AUTOSAR XML (schema 4-0-3)
standard types defined: Boolean, UInt16, UInt32
package /AUTOSAR_Platform/DataConstrs
  range DC_Boolean: raw 0..1
  range DC_UInt16: raw 0..65535
package /PATAC/MSM/ComponentTypes
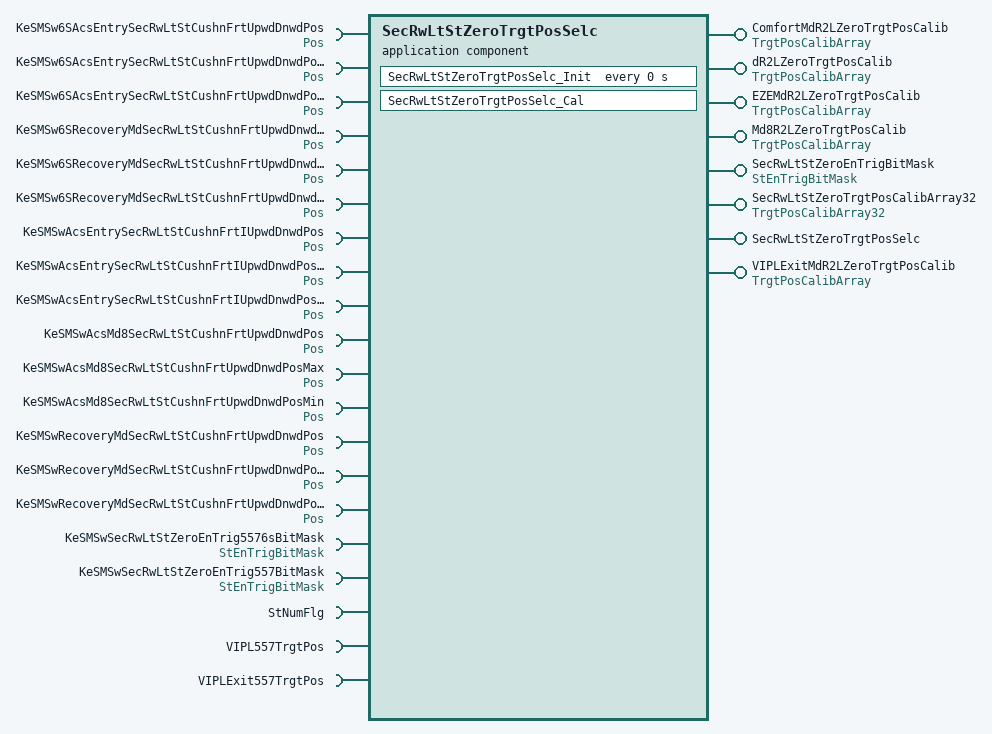
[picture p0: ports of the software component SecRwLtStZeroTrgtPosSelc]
  application sw component type SecRwLtStZeroTrgtPosSelc
    8 x provide port:
      ComfortMdR2LZeroTrgtPosCalib: nonqueued-sender-com-spec{data-element=TrgtPosArray, init-value=[4095, 4095, 4095]}, provided-interface=TrgtPosCalibArray
      dR2LZeroTrgtPosCalib: nonqueued-sender-com-spec{data-element=TrgtPosArray, init-value=[4095, 4095, 4095]}, provided-interface=TrgtPosCalibArray
      EZEMdR2LZeroTrgtPosCalib: nonqueued-sender-com-spec{data-element=TrgtPosArray, init-value=[4095, 4095, 4095]}, provided-interface=TrgtPosCalibArray
      Md8R2LZeroTrgtPosCalib: nonqueued-sender-com-spec{data-element=TrgtPosArray, init-value=[4095, 4095, 4095]}, provided-interface=TrgtPosCalibArray
      SecRwLtStZeroEnTrigBitMask: nonqueued-sender-com-spec{data-element=Val, init-value=0}, provided-interface=StEnTrigBitMask
      SecRwLtStZeroTrgtPosCalibArray32: nonqueued-sender-com-spec{data-element=TrgtPosArray32, init-value=96 x 4095}, provided-interface=TrgtPosCalibArray32
      SecRwLtStZeroTrgtPosSelc: server-com-spec{operation=Cal, queue-length=1}, provided-interface=SecRwLtStZeroTrgtPosSelc
      VIPLExitMdR2LZeroTrgtPosCalib: nonqueued-sender-com-spec{data-element=TrgtPosArray, init-value=[4095, 4095, 4095]}, provided-interface=TrgtPosCalibArray
    20 x require port:
      KeSMSw6SAcsEntrySecRwLtStCushnFrtUpwdDnwdPos: parameter-require-com-spec{init-value=0, parameter=Pos/Val}, required-interface=Pos
      KeSMSw6SAcsEntrySecRwLtStCushnFrtUpwdDnwdPosMax: parameter-require-com-spec{init-value=0, parameter=Pos/Val}, required-interface=Pos
      KeSMSw6SAcsEntrySecRwLtStCushnFrtUpwdDnwdPosMin: parameter-require-com-spec{init-value=0, parameter=Pos/Val}, required-interface=Pos
      KeSMSw6SRecoveryMdSecRwLtStCushnFrtUpwdDnwdPos: parameter-require-com-spec{init-value=0, parameter=Pos/Val}, required-interface=Pos
      KeSMSw6SRecoveryMdSecRwLtStCushnFrtUpwdDnwdPosMax: parameter-require-com-spec{init-value=0, parameter=Pos/Val}, required-interface=Pos
      KeSMSw6SRecoveryMdSecRwLtStCushnFrtUpwdDnwdPosMin: parameter-require-com-spec{init-value=0, parameter=Pos/Val}, required-interface=Pos
      KeSMSwAcsEntrySecRwLtStCushnFrtIUpwdDnwdPos: parameter-require-com-spec{init-value=0, parameter=Pos/Val}, required-interface=Pos
      KeSMSwAcsEntrySecRwLtStCushnFrtIUpwdDnwdPosMax: parameter-require-com-spec{init-value=0, parameter=Pos/Val}, required-interface=Pos
      KeSMSwAcsEntrySecRwLtStCushnFrtIUpwdDnwdPosMin: parameter-require-com-spec{init-value=0, parameter=Pos/Val}, required-interface=Pos
      KeSMSwAcsMd8SecRwLtStCushnFrtUpwdDnwdPos: parameter-require-com-spec{init-value=0, parameter=Pos/Val}, required-interface=Pos
      KeSMSwAcsMd8SecRwLtStCushnFrtUpwdDnwdPosMax: parameter-require-com-spec{init-value=0, parameter=Pos/Val}, required-interface=Pos
      KeSMSwAcsMd8SecRwLtStCushnFrtUpwdDnwdPosMin: parameter-require-com-spec{init-value=0, parameter=Pos/Val}, required-interface=Pos
      KeSMSwRecoveryMdSecRwLtStCushnFrtUpwdDnwdPos: parameter-require-com-spec{init-value=0, parameter=Pos/Val}, required-interface=Pos
      KeSMSwRecoveryMdSecRwLtStCushnFrtUpwdDnwdPosMax: parameter-require-com-spec{init-value=0, parameter=Pos/Val}, required-interface=Pos
      KeSMSwRecoveryMdSecRwLtStCushnFrtUpwdDnwdPosMin: parameter-require-com-spec{init-value=0, parameter=Pos/Val}, required-interface=Pos
      KeSMSwSecRwLtStZeroEnTrig5576sBitMask: parameter-require-com-spec{init-value=6153, parameter=StEnTrigBitMask/Val}, required-interface=StEnTrigBitMask
      KeSMSwSecRwLtStZeroEnTrig557BitMask: parameter-require-com-spec{init-value=6153, parameter=StEnTrigBitMask/Val}, required-interface=StEnTrigBitMask
      StNumFlg: required-interface=StNumFlg
        required-com-specs:
          data-element=Is4s, filter=data-filter-type=ALWAYS, init-value=0
          data-element=Is6s, filter=data-filter-type=ALWAYS, init-value=0
          data-element=Is6s7s, filter=data-filter-type=ALWAYS, init-value=0
          data-element=Is7s, filter=data-filter-type=ALWAYS, init-value=0
      VIPL557TrgtPos: required-com-specs=[VIPL557TrgtPos/Get, VIPL557TrgtPos/Set], required-interface=VIPL557TrgtPos
      VIPLExit557TrgtPos: required-com-specs=[VIPLExit557TrgtPos/Get, VIPLExit557TrgtPos/Set], required-interface=VIPLExit557TrgtPos
    behavior SecRwLtStZeroTrgtPosSelc_InternalBehavior
      operation invoked event OIT_SecRwLtStZeroTrgtPosSelc_Cal_SecRwLtStZeroTrgtPosSelc_Cal: start-on-event=SecRwLtStZeroTrgtPosSelc_Cal, operation=SecRwLtStZeroTrgtPosSelc.Cal
      timing event SecRwLtStZeroTrgtPosSelc_InitEvent: start-on-event=SecRwLtStZeroTrgtPosSelc_Init, period=0
      runnable SecRwLtStZeroTrgtPosSelc_Cal
        data-receive-point-by-arguments:
          4 x access:
            REC_StNumFlg_Is4s: accessed-variable=StNumFlg.Is4s
            REC_StNumFlg_Is6s: accessed-variable=StNumFlg.Is6s
            REC_StNumFlg_Is6s7s: accessed-variable=StNumFlg.Is6s7s
            REC_StNumFlg_Is7s: accessed-variable=StNumFlg.Is7s
        data-send-points:
          7 x access:
            SEND_ComfortMdR2LZeroTrgtPosCalib_TrgtPosArray: accessed-variable=ComfortMdR2LZeroTrgtPosCalib.TrgtPosArray
            SEND_EZEMdR2LZeroTrgtPosCalib_TrgtPosArray: accessed-variable=EZEMdR2LZeroTrgtPosCalib.TrgtPosArray
            SEND_Md8R2LZeroTrgtPosCalib_TrgtPosArray: accessed-variable=Md8R2LZeroTrgtPosCalib.TrgtPosArray
            SEND_SecRwLtStZeroEnTrigBitMask_Val: accessed-variable=SecRwLtStZeroEnTrigBitMask.Val
            SEND_SecRwLtStZeroTrgtPosCalibArray32_TrgtPosArray32: accessed-variable=SecRwLtStZeroTrgtPosCalibArray32.TrgtPosArray32
            SEND_VIPLExitMdR2LZeroTrgtPosCalib_TrgtPosArray: accessed-variable=VIPLExitMdR2LZeroTrgtPosCalib.TrgtPosArray
            SEND_VIPLMdR2LZeroTrgtPosCalib_TrgtPosArray: accessed-variable=dR2LZeroTrgtPosCalib.TrgtPosArray
        17 x parameter access:
          PA_KeSMSw6SAcsEntrySecRwLtStCushnFrtUpwdDnwdPos_Val: accessed-parameter=KeSMSw6SAcsEntrySecRwLtStCushnFrtUpwdDnwdPos.Val
          PA_KeSMSw6SAcsEntrySecRwLtStCushnFrtUpwdDnwdPosMax_Val: accessed-parameter=KeSMSw6SAcsEntrySecRwLtStCushnFrtUpwdDnwdPosMax.Val
          PA_KeSMSw6SAcsEntrySecRwLtStCushnFrtUpwdDnwdPosMin_Val: accessed-parameter=KeSMSw6SAcsEntrySecRwLtStCushnFrtUpwdDnwdPosMin.Val
          PA_KeSMSw6SRecoveryMdSecRwLtStCushnFrtUpwdDnwdPos_Val: accessed-parameter=KeSMSw6SRecoveryMdSecRwLtStCushnFrtUpwdDnwdPos.Val
          PA_KeSMSw6SRecoveryMdSecRwLtStCushnFrtUpwdDnwdPosMax_Val: accessed-parameter=KeSMSw6SRecoveryMdSecRwLtStCushnFrtUpwdDnwdPosMax.Val
          PA_KeSMSw6SRecoveryMdSecRwLtStCushnFrtUpwdDnwdPosMin_Val: accessed-parameter=KeSMSw6SRecoveryMdSecRwLtStCushnFrtUpwdDnwdPosMin.Val
          PA_KeSMSwAcsEntrySecRwLtStCushnFrtIUpwdDnwdPos_Val: accessed-parameter=KeSMSwAcsEntrySecRwLtStCushnFrtIUpwdDnwdPos.Val
          PA_KeSMSwAcsEntrySecRwLtStCushnFrtIUpwdDnwdPosMax_Val: accessed-parameter=KeSMSwAcsEntrySecRwLtStCushnFrtIUpwdDnwdPosMax.Val
          PA_KeSMSwAcsEntrySecRwLtStCushnFrtIUpwdDnwdPosMin_Val: accessed-parameter=KeSMSwAcsEntrySecRwLtStCushnFrtIUpwdDnwdPosMin.Val
          PA_KeSMSwAcsMd8SecRwLtStCushnFrtUpwdDnwdPos_Val: accessed-parameter=KeSMSwAcsMd8SecRwLtStCushnFrtUpwdDnwdPos.Val
          PA_KeSMSwAcsMd8SecRwLtStCushnFrtUpwdDnwdPosMax_Val: accessed-parameter=KeSMSwAcsMd8SecRwLtStCushnFrtUpwdDnwdPosMax.Val
          PA_KeSMSwAcsMd8SecRwLtStCushnFrtUpwdDnwdPosMin_Val: accessed-parameter=KeSMSwAcsMd8SecRwLtStCushnFrtUpwdDnwdPosMin.Val
          PA_KeSMSwRecoveryMdSecRwLtStCushnFrtUpwdDnwdPos_Val: accessed-parameter=KeSMSwRecoveryMdSecRwLtStCushnFrtUpwdDnwdPos.Val
          PA_KeSMSwRecoveryMdSecRwLtStCushnFrtUpwdDnwdPosMax_Val: accessed-parameter=KeSMSwRecoveryMdSecRwLtStCushnFrtUpwdDnwdPosMax.Val
          PA_KeSMSwRecoveryMdSecRwLtStCushnFrtUpwdDnwdPosMin_Val: accessed-parameter=KeSMSwRecoveryMdSecRwLtStCushnFrtUpwdDnwdPosMin.Val
          PA_KeSMSwSecRwLtStZeroEnTrig5576sBitMask_Val: accessed-parameter=KeSMSwSecRwLtStZeroEnTrig5576sBitMask.Val
          PA_KeSMSwSecRwLtStZeroEnTrig557BitMask_Val: accessed-parameter=KeSMSwSecRwLtStZeroEnTrig557BitMask.Val
        sync call SC_VIPL557TrgtPos_Get: operation=VIPL557TrgtPos.Get, timeout=0
        sync call SC_VIPLExit557TrgtPos_Get: operation=VIPLExit557TrgtPos.Get, timeout=0
      runnable SecRwLtStZeroTrgtPosSelc_Init
        17 x parameter access:
          PA_KeSMSw6SAcsEntrySecRwLtStCushnFrtUpwdDnwdPos_Val: accessed-parameter=KeSMSw6SAcsEntrySecRwLtStCushnFrtUpwdDnwdPos.Val
          PA_KeSMSw6SAcsEntrySecRwLtStCushnFrtUpwdDnwdPosMax_Val: accessed-parameter=KeSMSw6SAcsEntrySecRwLtStCushnFrtUpwdDnwdPosMax.Val
          PA_KeSMSw6SAcsEntrySecRwLtStCushnFrtUpwdDnwdPosMin_Val: accessed-parameter=KeSMSw6SAcsEntrySecRwLtStCushnFrtUpwdDnwdPosMin.Val
          PA_KeSMSw6SRecoveryMdSecRwLtStCushnFrtUpwdDnwdPos_Val: accessed-parameter=KeSMSw6SRecoveryMdSecRwLtStCushnFrtUpwdDnwdPos.Val
          PA_KeSMSw6SRecoveryMdSecRwLtStCushnFrtUpwdDnwdPosMax_Val: accessed-parameter=KeSMSw6SRecoveryMdSecRwLtStCushnFrtUpwdDnwdPosMax.Val
          PA_KeSMSw6SRecoveryMdSecRwLtStCushnFrtUpwdDnwdPosMin_Val: accessed-parameter=KeSMSw6SRecoveryMdSecRwLtStCushnFrtUpwdDnwdPosMin.Val
          PA_KeSMSwAcsEntrySecRwLtStCushnFrtIUpwdDnwdPos_Val: accessed-parameter=KeSMSwAcsEntrySecRwLtStCushnFrtIUpwdDnwdPos.Val
          PA_KeSMSwAcsEntrySecRwLtStCushnFrtIUpwdDnwdPosMax_Val: accessed-parameter=KeSMSwAcsEntrySecRwLtStCushnFrtIUpwdDnwdPosMax.Val
          PA_KeSMSwAcsEntrySecRwLtStCushnFrtIUpwdDnwdPosMin_Val: accessed-parameter=KeSMSwAcsEntrySecRwLtStCushnFrtIUpwdDnwdPosMin.Val
          PA_KeSMSwAcsMd8SecRwLtStCushnFrtUpwdDnwdPos_Val: accessed-parameter=KeSMSwAcsMd8SecRwLtStCushnFrtUpwdDnwdPos.Val
          PA_KeSMSwAcsMd8SecRwLtStCushnFrtUpwdDnwdPosMax_Val: accessed-parameter=KeSMSwAcsMd8SecRwLtStCushnFrtUpwdDnwdPosMax.Val
          PA_KeSMSwAcsMd8SecRwLtStCushnFrtUpwdDnwdPosMin_Val: accessed-parameter=KeSMSwAcsMd8SecRwLtStCushnFrtUpwdDnwdPosMin.Val
          PA_KeSMSwRecoveryMdSecRwLtStCushnFrtUpwdDnwdPos_Val: accessed-parameter=KeSMSwRecoveryMdSecRwLtStCushnFrtUpwdDnwdPos.Val
          PA_KeSMSwRecoveryMdSecRwLtStCushnFrtUpwdDnwdPosMax_Val: accessed-parameter=KeSMSwRecoveryMdSecRwLtStCushnFrtUpwdDnwdPosMax.Val
          PA_KeSMSwRecoveryMdSecRwLtStCushnFrtUpwdDnwdPosMin_Val: accessed-parameter=KeSMSwRecoveryMdSecRwLtStCushnFrtUpwdDnwdPosMin.Val
          PA_KeSMSwSecRwLtStZeroEnTrig5576sBitMask_Val: accessed-parameter=KeSMSwSecRwLtStZeroEnTrig5576sBitMask.Val
          PA_KeSMSwSecRwLtStZeroEnTrig557BitMask_Val: accessed-parameter=KeSMSwSecRwLtStZeroEnTrig557BitMask.Val
  swc implementation SecRwLtStZeroTrgtPosSelc_Implementation: behavior=SecRwLtStZeroTrgtPosSelc_InternalBehavior
    code-descriptors:
      code Default: artifact-descriptors=autosar-engineering-object={short-label=Default, category=SWSRC}
package /PATAC/MSM/ModeAdjust/CalPortInterface
  parameter interface Pos
    parameter data prototype Val: sw-calibration-access=READ-WRITE, type=UInt16
  parameter interface StEnTrigBitMask
    parameter data prototype Val: sw-calibration-access=READ-WRITE, type=UInt32
package /PATAC/MSM/ModeAdjust/DataType
  impl type TrgtPosCalibArray: category=ARRAY, sw-calibration-access=READ-ONLY, type-emitter=RTE  # 0:pos 1:max 2:min
    element Element: array-size=3, array-size-semantics=FIXED-SIZE, implementation-data-type=UInt16, invalid-value=0
  impl type TrgtPosCalibArray32: category=ARRAY, sw-calibration-access=READ-ONLY, type-emitter=RTE  # 0:pos 1:max 2:min
    element Element: array-size=96, array-size-semantics=FIXED-SIZE, implementation-data-type=UInt16, invalid-value=0
package /PATAC/MSM/ModeAdjust/PortInterface
  client server interface SecRwLtStZeroTrgtPosSelc
    operation Cal
  client server interface VIPL557TrgtPos
    operation Get
      5 x arg, all with type=UInt16, direction=OUT, server-argument-impl-policy=USE-ARGUMENT-TYPE:
        SecRwLtStBkReclnTrgtPos
        SecRwLtStZeroTrgtPos
        SecRwLtStLgrstUpwdDnwdTrgtPos
        SecRwLtStLgrstInwdOtwdTrgtPos
        SecRwLtStFwdBkwdTrgtPos
    operation Set
      5 x arg, all with type=UInt16, direction=IN, server-argument-impl-policy=USE-ARGUMENT-TYPE:
        SecRwLtStBkReclnTrgtPos
        SecRwLtStZeroTrgtPos
        SecRwLtStLgrstUpwdDnwdTrgtPos
        SecRwLtStLgrstInwdOtwdTrgtPos
        SecRwLtStFwdBkwdTrgtPos
  client server interface VIPLExit557TrgtPos
    operation Get
      7 x arg, all with type=UInt16, direction=OUT, server-argument-impl-policy=USE-ARGUMENT-TYPE:
        SecRwLtStBkReclnTrgtPos
        SecRwLtStZeroTrgtPos
        SecRwLtStLgrstUpwdDnwdTrgtPos
        SecRwLtStLgrstInwdOtwdTrgtPos
        ThdRwLtStBkReclnTrgtPos
        ThdRwLtStFwdBkwdTrgtPos
        SecRwLtStFwdBkwdTrgtPos
    operation Set
  4 x sender receiver interface:
    StEnTrigBitMask: invalidation-policy{data-element=Val, handle-invalid=DONT-INVALIDATE}
      data Val: type=UInt32
    StNumFlg
      4 x data, all with type=Boolean:
        Is4s
        Is6s
        Is6s7s
        Is7s
      invalidation-policys:
        data-element=Is4s, handle-invalid=DONT-INVALIDATE
        data-element=Is6s, handle-invalid=DONT-INVALIDATE
        data-element=Is6s7s, handle-invalid=DONT-INVALIDATE
        data-element=Is7s, handle-invalid=DONT-INVALIDATE
    TrgtPosCalibArray: invalidation-policy{data-element=TrgtPosArray, handle-invalid=DONT-INVALIDATE}
      data TrgtPosArray: type=TrgtPosCalibArray  # 0:Pos 1:Max 2:Min
    TrgtPosCalibArray32: invalidation-policy{data-element=TrgtPosArray32, handle-invalid=DONT-INVALIDATE}
      data TrgtPosArray32: type=TrgtPosCalibArray32  # 0:Pos 1:Max 2:Min
